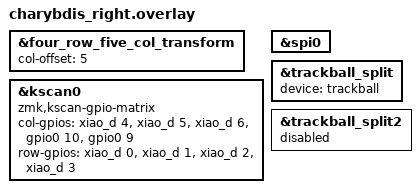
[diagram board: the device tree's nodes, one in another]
#include "charybdis.dtsi"
#include "charybdis_3610.dtsi"
#include "split_input_common.dtsi"

&four_row_five_col_transform {
	col-offset = <5>;  // 右手は5列目から開始
};

&kscan0 {
  compatible = "zmk,kscan-gpio-matrix";
  
  // 4行5列用に変更されたGPIO設定
  col-gpios
    = <&xiao_d 4 GPIO_ACTIVE_HIGH>   // 列0
    , <&xiao_d 5 GPIO_ACTIVE_HIGH>  // 列1
    , <&xiao_d 6 GPIO_ACTIVE_HIGH>  // 列2
    , <&gpio0 10 GPIO_ACTIVE_HIGH>  // 列3
    , <&gpio0 9 GPIO_ACTIVE_HIGH>  // 列4
    ;

  row-gpios
    = <&xiao_d 0 (GPIO_ACTIVE_HIGH | GPIO_PULL_DOWN)>   // 行0
    , <&xiao_d 1 (GPIO_ACTIVE_HIGH | GPIO_PULL_DOWN)>   // 行1
    , <&xiao_d 2 (GPIO_ACTIVE_HIGH | GPIO_PULL_DOWN)>   // 行2
    , <&xiao_d 3 (GPIO_ACTIVE_HIGH | GPIO_PULL_DOWN)>   // 行3
    ;
};

&spi0 {
    status = "okay";
};

&trackball_split { 
	device = <&trackball>; 
};

&trackball_split2 { 
	status = "disabled"; 
};
